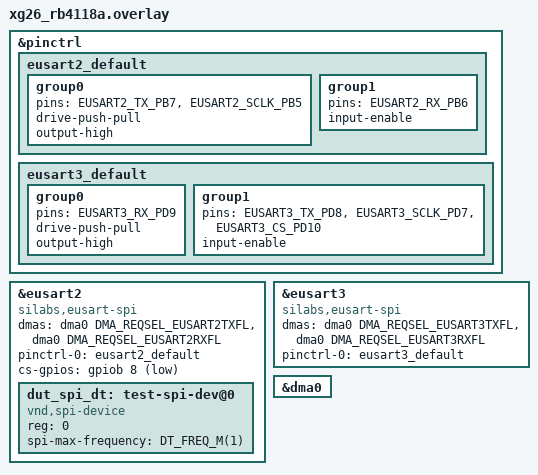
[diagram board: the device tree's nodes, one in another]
/*
 * Copyright (c) 2026 Silicon Laboratories Inc.
 *
 * SPDX-License-Identifier: Apache-2.0
 */

#include <zephyr/dt-bindings/pinctrl/silabs/xg26-pinctrl.h>

/*
 * Four loopbacks are required:
 * PB5 - PD7: eusart2 SCLK to eusart3 SCLK
 * PB7 - PD8: eusart2 TX to eusart3 TX (MOSI)
 * PB6 - PD9: eusart2 RX to eusart3 RX (MISO)
 * PB8 - PD10: eusart2 cs-gpios to eusart3 CS
 *
 * In synchronous mode, the EUSART TX signal is MOSI and the RX signal is MISO
 * regardless of the operating mode, so the peripheral receives on TX and
 * transmits on RX.
 */

&pinctrl {
	eusart2_default: eusart2_default {
		group0 {
			pins = <EUSART2_TX_PB7>, <EUSART2_SCLK_PB5>;
			drive-push-pull;
			output-high;
		};

		group1 {
			pins = <EUSART2_RX_PB6>;
			input-enable;
		};
	};

	eusart3_default: eusart3_default {
		group0 {
			pins = <EUSART3_RX_PD9>;
			drive-push-pull;
			output-high;
		};

		group1 {
			pins = <EUSART3_TX_PD8>, <EUSART3_SCLK_PD7>, <EUSART3_CS_PD10>;
			input-enable;
		};
	};
};

&eusart2 {
	compatible = "silabs,eusart-spi";
	dmas = <&dma0 DMA_REQSEL_EUSART2TXFL>,
	       <&dma0 DMA_REQSEL_EUSART2RXFL>;
	dma-names = "tx", "rx";
	#address-cells = <1>;
	#size-cells = <0>;
	pinctrl-0 = <&eusart2_default>;
	pinctrl-names = "default";
	cs-gpios = <&gpiob 8 GPIO_ACTIVE_LOW>;
	status = "okay";

	dut_spi_dt: test-spi-dev@0 {
		compatible = "vnd,spi-device";
		reg = <0>;
		spi-max-frequency = <DT_FREQ_M(1)>;
	};
};

dut_spis: &eusart3 {
	compatible = "silabs,eusart-spi";
	/delete-property/ cs-gpios;
	dmas = <&dma0 DMA_REQSEL_EUSART3TXFL>,
	       <&dma0 DMA_REQSEL_EUSART3RXFL>;
	dma-names = "tx", "rx";
	#address-cells = <1>;
	#size-cells = <0>;
	pinctrl-0 = <&eusart3_default>;
	pinctrl-names = "default";
	status = "okay";
};

&dma0 {
	status = "okay";
};
